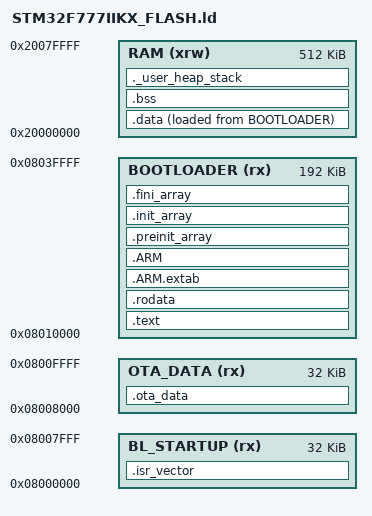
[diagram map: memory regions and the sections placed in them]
/**
 ******************************************************************************
 * @file      LinkerScript.ld
 * @author    Auto-generated by STM32CubeIDE
 * @brief     Linker script for STM32F777IIKx Device from STM32F7 series
 *                      2048Kbytes FLASH
 *                      512Kbytes RAM
 *
 *            Set heap size, stack size and stack location according
 *            to application requirements.
 *
 *            Set memory bank area and size if external memory is used
 ******************************************************************************
 * @attention
 *
 * <h2><center>&copy; Copyright (c) 2020 STMicroelectronics.
 * All rights reserved.</center></h2>
 *
 * This software component is licensed by ST under BSD 3-Clause license,
 * the "License"; You may not use this file except in compliance with the
 * License. You may obtain a copy of the License at:
 *                        opensource.org/licenses/BSD-3-Clause
 *
 ******************************************************************************
 */

/* Entry Point */
ENTRY(Reset_Handler)

/* Highest address of the user mode stack */
_estack = ORIGIN(RAM) + LENGTH(RAM);	/* end of "RAM" Ram type memory */

_Min_Heap_Size = 0x200 ;	/* required amount of heap  */
_Min_Stack_Size = 0x400 ;	/* required amount of stack */

/* Memories definition */
MEMORY
{
  RAM    (xrw)    : ORIGIN = 0x20000000,   LENGTH = 512K
  BL_STARTUP	(rx)	: ORIGIN = 0x08000000,	LENGTH = 32K
  OTA_DATA		(rx)	: ORIGIN = 0x08008000,	LENGTH = 32K
  BOOTLOADER    (rx)    : ORIGIN = 0x08010000,   LENGTH = 192K
}

/* Sections */
SECTIONS
{

/* The startup code into "BOOTLOADER" Rom type memory */
  .isr_vector :
  {
  	FILL(0xAA55AA55);
    . = ALIGN(4);
    KEEP(*(.isr_vector)) /* Startup code */
    . = ALIGN(4);
  } >BL_STARTUP

	/* Clear OTA data section when BL is flashed to set it to good known state */
	/* Some data has to be written so linker has something in the output section */
	/* This section can also be used to set some flags for testing purposes */
	.ota_data :
	{
		FILL(0xAA55AA55);
		. = ALIGN(4);
		
		. = ORIGIN(OTA_DATA);
		
		BYTE(0x00)	/*	UPDATE_FLAG_LOC	- SETTING THIS TO 1 WILL TRIGGER AN UPDATE	*/ 
		BYTE(0x00)	/*	ROLLBACK_FLAG_LOC- SETTING THIS TO 1 WILL TRIGGER A ROLLBACK	*/ 
		BYTE(0x00)	/*	BACKUP_FLAG_LOC	- SETTING THIS TO 1 WILL OVERWRITE THE SEC. IMAGE WITH PRI. IMAGE	*/
	  BYTE(0x00)	/*	UPDATE_FAIL_FLAG_LOC	- DIAGNOSTIC FLAG	*/ 
		BYTE(0x00)	/*	ROLLBACK_FLAG_LOC- DIAGNOSTIC FLAG	*/ 
		BYTE(0x00)	/*	BACKUP_FLAG_LOC	- DIAGNOSTIC FLAG	*/
		BYTE(0x00)	/*	ROLLBACK_ON_FAIL_BOOT_FLAG_LOC - SETTING THIS TO 1 WILL FORCE ROLLBACK ON BOOT FAIL	*/
		BYTE(0x00)	/*	RESERVED	*/
		
	} > OTA_DATA

  

  /* The program code and other data into "BOOTLOADER" Rom type memory */
  .text :
  {
  	FILL(0xAA55AA55);
    . = ALIGN(4);
    
    BYTE(0x00)		/* Bootloader Major Version	*/
    BYTE(0x01)		/* Bootloader Minor Version	*/

    *(.text)           /* .text sections (code) */
    *(.text*)          /* .text* sections (code) */
    *(.glue_7)         /* glue arm to thumb code */
    *(.glue_7t)        /* glue thumb to arm code */
    *(.eh_frame)

    KEEP (*(.init))
    KEEP (*(.fini))

    . = ALIGN(4);
    _etext = .;        /* define a global symbols at end of code */
  } >BOOTLOADER

  /* Constant data into "BOOTLOADER" Rom type memory */
  .rodata :
  {
    . = ALIGN(4);
    *(.rodata)         /* .rodata sections (constants, strings, etc.) */
    *(.rodata*)        /* .rodata* sections (constants, strings, etc.) */
    . = ALIGN(4);
  } >BOOTLOADER

  .ARM.extab   : { 
    . = ALIGN(4);
    *(.ARM.extab* .gnu.linkonce.armextab.*)
    . = ALIGN(4);
  } >BOOTLOADER
  
  .ARM : {
    . = ALIGN(4);
    __exidx_start = .;
    *(.ARM.exidx*)
    __exidx_end = .;
    . = ALIGN(4);
  } >BOOTLOADER

  .preinit_array     :
  {
    . = ALIGN(4);
    PROVIDE_HIDDEN (__preinit_array_start = .);
    KEEP (*(.preinit_array*))
    PROVIDE_HIDDEN (__preinit_array_end = .);
    . = ALIGN(4);
  } >BOOTLOADER
  
  .init_array :
  {
    . = ALIGN(4);
    PROVIDE_HIDDEN (__init_array_start = .);
    KEEP (*(SORT(.init_array.*)))
    KEEP (*(.init_array*))
    PROVIDE_HIDDEN (__init_array_end = .);
    . = ALIGN(4);
  } >BOOTLOADER
  
  .fini_array :
  {
    . = ALIGN(4);
    PROVIDE_HIDDEN (__fini_array_start = .);
    KEEP (*(SORT(.fini_array.*)))
    KEEP (*(.fini_array*))
    PROVIDE_HIDDEN (__fini_array_end = .);
    . = ALIGN(4);
  } >BOOTLOADER

  /* Used by the startup to initialize data */
  _sidata = LOADADDR(.data);

  /* Initialized data sections into "RAM" Ram type memory */
  .data : 
  {
    . = ALIGN(4);
    _sdata = .;        /* create a global symbol at data start */
    *(.data)           /* .data sections */
    *(.data*)          /* .data* sections */

    . = ALIGN(4);
    _edata = .;        /* define a global symbol at data end */
    
  } >RAM AT> BOOTLOADER

  /* Uninitialized data section into "RAM" Ram type memory */
  . = ALIGN(4);
  .bss :
  {
    /* This is used by the startup in order to initialize the .bss section */
    _sbss = .;         /* define a global symbol at bss start */
    __bss_start__ = _sbss;
    *(.bss)
    *(.bss*)
    *(COMMON)

    . = ALIGN(4);
    _ebss = .;         /* define a global symbol at bss end */
    __bss_end__ = _ebss;
  } >RAM

  /* User_heap_stack section, used to check that there is enough "RAM" Ram  type memory left */
  ._user_heap_stack :
  {
    . = ALIGN(8);
    PROVIDE ( end = . );
    PROVIDE ( _end = . );
    . = . + _Min_Heap_Size;
    . = . + _Min_Stack_Size;
    . = ALIGN(8);
  } >RAM

  /* Remove information from the compiler libraries */
  /DISCARD/ :
  {
    libc.a ( * )
    libm.a ( * )
    libgcc.a ( * )
  }

  .ARM.attributes 0 : { *(.ARM.attributes) }
}
